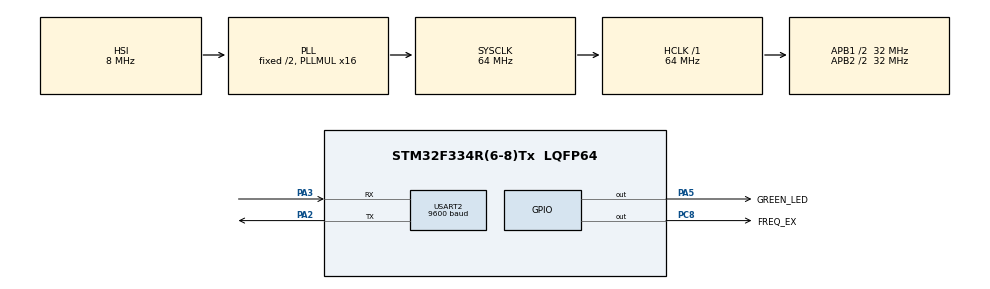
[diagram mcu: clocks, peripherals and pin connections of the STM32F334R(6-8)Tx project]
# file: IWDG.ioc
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IWDG.Prescaler=IWDG_PRESCALER_128
IWDG.Reload=1000
IWDG.Window=0
Mcu.Family=STM32F3
Mcu.Name=STM32F334R(6-8)Tx
Mcu.Package=LQFP64
NVIC.PriorityGroup=NVIC_PRIORITYGROUP_0
NVIC.TIM3_IRQn=true\:0\:0\:false\:false\:true\:true\:true\:true
PA2.Mode=Asynchronous
PA2.Signal=USART2_TX
PA3.Mode=Asynchronous
PA3.Signal=USART2_RX
PA5.GPIO_Label=GREEN_LED
PA5.Signal=GPIO_Output
PC6.Signal=S_TIM3_CH1
PC8.GPIO_Label=FREQ_EX
PC8.Signal=GPIO_Output
ProjectManager.HeapSize=0x200
ProjectManager.StackSize=0x400
ProjectManager.TargetToolchain=STM32CubeIDE
RCC.AHBFreq_Value=64000000
RCC.APB1CLKDivider=RCC_HCLK_DIV2
RCC.APB1Freq_Value=32000000
RCC.APB1TimFreq_Value=64000000
RCC.APB2CLKDivider=RCC_HCLK_DIV2
RCC.APB2Freq_Value=32000000
RCC.APB2TimFreq_Value=64000000
RCC.CortexFreq_Value=64000000
RCC.FLatency-AdvancedSettings=FLASH_LATENCY_2
RCC.HCLKFreq_Value=64000000
RCC.HSE_VALUE=8000000
RCC.HSI_VALUE=8000000
RCC.LSE_VALUE=32768
RCC.PLLMUL=RCC_PLL_MUL16
RCC.SYSCLKFreq_VALUE=64000000
RCC.SYSCLKSourceVirtual=RCC_SYSCLKSOURCE_PLLCLK
SH.S_TIM3_CH1.0=TIM3_CH1
TIM3.Channel-Output\ Compare1\ No\ Output=TIM_CHANNEL_1
TIM3.Period=31984
TIM3.Prescaler=2000
USART2.BaudRate=9600
USART2.Mode=MODE_TX_RX
USART2.OverSampling=UART_OVERSAMPLING_8
USART2.VirtualMode-Asynchronous=VM_ASYNC
VP_IWDG_VS_IWDG.Mode=IWDG_Activate
VP_TIM3_VS_ClockSourceINT.Mode=Internal
VP_TIM3_VS_no_output1.Mode=Output Compare1 No Output
board=NUCLEO-F334R8

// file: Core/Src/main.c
/* USER CODE BEGIN Header */
/**
  ******************************************************************************
  * @file           : main.c
  * @brief          : Main program body
  ******************************************************************************
  * @attention
  *
  * Copyright (c) 2024 STMicroelectronics.
  * All rights reserved.
  *
  * This software is licensed under terms that can be found in the LICENSE file
  * in the root directory of this software component.
  * If no LICENSE file comes with this software, it is provided AS-IS.
  *
  ******************************************************************************
  */
/* USER CODE END Header */
#include "main.h"

IWDG_HandleTypeDef hiwdg;

TIM_HandleTypeDef htim3;

UART_HandleTypeDef huart2;

void SystemClock_Config(void);
static void MX_GPIO_Init(void);
static void MX_USART2_UART_Init(void);
static void MX_TIM3_Init(void);
static void MX_IWDG_Init(void);
/* USER CODE BEGIN PFP */
static const char *starting_buff = "Starting\r\n";

/* USER CODE END PFP */

int main(void)
{

  /* MCU Configuration--------------------------------------------------------*/

  /* Reset of all peripherals, Initializes the Flash interface and the Systick. */
  HAL_Init();

  /* Configure the system clock */
  SystemClock_Config();

  /* Initialize all configured peripherals */
  MX_GPIO_Init();
  MX_USART2_UART_Init();
  MX_TIM3_Init();
  MX_IWDG_Init();
  /* USER CODE BEGIN 2 */
  HAL_Delay(1);
  (void)HAL_UART_Transmit(&huart2, (uint8_t *)starting_buff, 10, 100);

  /* USER CODE END 2 */

  /* Infinite loop */
  while (1)
  {

    /* USER CODE BEGIN 3 */
	  HAL_GPIO_WritePin(GREEN_LED_GPIO_Port, GREEN_LED_Pin, GPIO_PIN_SET);
	  HAL_Delay(5000);
  }
  /* USER CODE END 3 */
}

void SystemClock_Config(void)
{
  RCC_OscInitTypeDef RCC_OscInitStruct = {0};
  RCC_ClkInitTypeDef RCC_ClkInitStruct = {0};

  /** Initializes the RCC Oscillators according to the specified parameters
  * in the RCC_OscInitTypeDef structure.
  */
  RCC_OscInitStruct.OscillatorType = RCC_OSCILLATORTYPE_HSI|RCC_OSCILLATORTYPE_LSI;
  RCC_OscInitStruct.HSIState = RCC_HSI_ON;
  RCC_OscInitStruct.HSICalibrationValue = RCC_HSICALIBRATION_DEFAULT;
  RCC_OscInitStruct.LSIState = RCC_LSI_ON;
  RCC_OscInitStruct.PLL.PLLState = RCC_PLL_ON;
  RCC_OscInitStruct.PLL.PLLSource = RCC_PLLSOURCE_HSI;
  RCC_OscInitStruct.PLL.PLLMUL = RCC_PLL_MUL16;
  if (HAL_RCC_OscConfig(&RCC_OscInitStruct) != HAL_OK)
  {
    Error_Handler();
  }

  /** Initializes the CPU, AHB and APB buses clocks
  */
  RCC_ClkInitStruct.ClockType = RCC_CLOCKTYPE_HCLK|RCC_CLOCKTYPE_SYSCLK
                              |RCC_CLOCKTYPE_PCLK1|RCC_CLOCKTYPE_PCLK2;
  RCC_ClkInitStruct.SYSCLKSource = RCC_SYSCLKSOURCE_PLLCLK;
  RCC_ClkInitStruct.AHBCLKDivider = RCC_SYSCLK_DIV1;
  RCC_ClkInitStruct.APB1CLKDivider = RCC_HCLK_DIV2;
  RCC_ClkInitStruct.APB2CLKDivider = RCC_HCLK_DIV2;

  if (HAL_RCC_ClockConfig(&RCC_ClkInitStruct, FLASH_LATENCY_2) != HAL_OK)
  {
    Error_Handler();
  }
}

static void MX_IWDG_Init(void)
{

  hiwdg.Instance = IWDG;
  hiwdg.Init.Prescaler = IWDG_PRESCALER_128;
  hiwdg.Init.Window = 0;
  hiwdg.Init.Reload = 1000;
  if (HAL_IWDG_Init(&hiwdg) != HAL_OK)
  {
    Error_Handler();
  }

}

static void MX_TIM3_Init(void)
{

  TIM_ClockConfigTypeDef sClockSourceConfig = {0};
  TIM_MasterConfigTypeDef sMasterConfig = {0};
  TIM_OC_InitTypeDef sConfigOC = {0};

  htim3.Instance = TIM3;
  htim3.Init.Prescaler = 2000;
  htim3.Init.CounterMode = TIM_COUNTERMODE_UP;
  htim3.Init.Period = 31984;
  htim3.Init.ClockDivision = TIM_CLOCKDIVISION_DIV1;
  htim3.Init.AutoReloadPreload = TIM_AUTORELOAD_PRELOAD_DISABLE;
  if (HAL_TIM_Base_Init(&htim3) != HAL_OK)
  {
    Error_Handler();
  }
  sClockSourceConfig.ClockSource = TIM_CLOCKSOURCE_INTERNAL;
  if (HAL_TIM_ConfigClockSource(&htim3, &sClockSourceConfig) != HAL_OK)
  {
    Error_Handler();
  }
  if (HAL_TIM_OC_Init(&htim3) != HAL_OK)
  {
    Error_Handler();
  }
  sMasterConfig.MasterOutputTrigger = TIM_TRGO_RESET;
  sMasterConfig.MasterSlaveMode = TIM_MASTERSLAVEMODE_DISABLE;
  if (HAL_TIMEx_MasterConfigSynchronization(&htim3, &sMasterConfig) != HAL_OK)
  {
    Error_Handler();
  }
  sConfigOC.OCMode = TIM_OCMODE_TIMING;
  sConfigOC.Pulse = 0;
  sConfigOC.OCPolarity = TIM_OCPOLARITY_HIGH;
  sConfigOC.OCFastMode = TIM_OCFAST_DISABLE;
  if (HAL_TIM_OC_ConfigChannel(&htim3, &sConfigOC, TIM_CHANNEL_1) != HAL_OK)
  {
    Error_Handler();
  }

}

static void MX_USART2_UART_Init(void)
{

  huart2.Instance = USART2;
  huart2.Init.BaudRate = 9600;
  huart2.Init.WordLength = UART_WORDLENGTH_8B;
  huart2.Init.StopBits = UART_STOPBITS_1;
  huart2.Init.Parity = UART_PARITY_NONE;
  huart2.Init.Mode = UART_MODE_TX_RX;
  huart2.Init.HwFlowCtl = UART_HWCONTROL_NONE;
  huart2.Init.OverSampling = UART_OVERSAMPLING_8;
  huart2.Init.OneBitSampling = UART_ONE_BIT_SAMPLE_DISABLE;
  huart2.AdvancedInit.AdvFeatureInit = UART_ADVFEATURE_NO_INIT;
  if (HAL_UART_Init(&huart2) != HAL_OK)
  {
    Error_Handler();
  }

}

static void MX_GPIO_Init(void)
{
  GPIO_InitTypeDef GPIO_InitStruct = {0};

  /* GPIO Ports Clock Enable */
  __HAL_RCC_GPIOA_CLK_ENABLE();
  __HAL_RCC_GPIOC_CLK_ENABLE();

  /*Configure GPIO pin Output Level */
  HAL_GPIO_WritePin(GREEN_LED_GPIO_Port, GREEN_LED_Pin, GPIO_PIN_RESET);

  /*Configure GPIO pin Output Level */
  HAL_GPIO_WritePin(FREQ_EX_GPIO_Port, FREQ_EX_Pin, GPIO_PIN_RESET);

  /*Configure GPIO pin : GREEN_LED_Pin */
  GPIO_InitStruct.Pin = GREEN_LED_Pin;
  GPIO_InitStruct.Mode = GPIO_MODE_OUTPUT_PP;
  GPIO_InitStruct.Pull = GPIO_NOPULL;
  GPIO_InitStruct.Speed = GPIO_SPEED_FREQ_LOW;
  HAL_GPIO_Init(GREEN_LED_GPIO_Port, &GPIO_InitStruct);

  /*Configure GPIO pin : FREQ_EX_Pin */
  GPIO_InitStruct.Pin = FREQ_EX_Pin;
  GPIO_InitStruct.Mode = GPIO_MODE_OUTPUT_PP;
  GPIO_InitStruct.Pull = GPIO_NOPULL;
  GPIO_InitStruct.Speed = GPIO_SPEED_FREQ_LOW;
  HAL_GPIO_Init(FREQ_EX_GPIO_Port, &GPIO_InitStruct);

}

void Error_Handler(void)
{
  __disable_irq();
  while (1)
  {
  }
}
